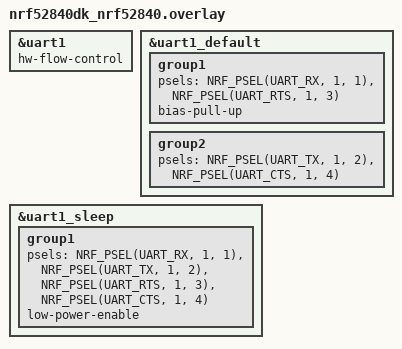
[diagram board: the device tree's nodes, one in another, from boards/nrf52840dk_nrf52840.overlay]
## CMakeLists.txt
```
#
# Copyright (c) 2024 Nordic Semiconductor ASA
#
# SPDX-License-Identifier: LicenseRef-Nordic-5-Clause
#
cmake_minimum_required(VERSION 3.20.0)

find_package(Zephyr REQUIRED HINTS $ENV{ZEPHYR_BASE})

project(nrf_rpc_remote)

# NORDIC SDK APP START
target_sources(app PRIVATE src/main.c)
# NORDIC SDK APP END

# Link OpenThread CLI even though OPENTHREAD_SHELL is not selected
zephyr_link_libraries(openthread-cli-ftd)
```

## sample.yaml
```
sample:
  name: nRF RPC application
  description: Test nRF RPC application
tests:
  sample.remote.rpc_ble:
    build_only: true
    platform_allow: >
      nrf52840dk_nrf52840
    tags: ci_build
    extra_args: >
      SNIPPET="ble"
    integration_platforms:
      - nrf52840dk_nrf52840
  sample.remote.rpc_ot:
    build_only: true
    platform_allow: >
      nrf52840dk_nrf52840
    tags: ci_build
    extra_args: >
      SNIPPET="openthread"
    integration_platforms:
      - nrf52840dk_nrf52840
  sample.remote.rpc:
    build_only: true
    platform_allow: >
      nrf52840dk_nrf52840
    tags: ci_build
    extra_args: >
      SNIPPET="ble;openthread"
    integration_platforms:
      - nrf52840dk_nrf52840
```

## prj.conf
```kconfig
#
# Copyright (c) 2024 Nordic Semiconductor
#
# SPDX-License-Identifier: LicenseRef-Nordic-5-Clause
#
CONFIG_HEAP_MEM_POOL_SIZE=4096

CONFIG_THREAD_CUSTOM_DATA=y

CONFIG_NRF_RPC=y
CONFIG_NRF_RPC_CBOR=y
CONFIG_NRF_RPC_THREAD_STACK_SIZE=4096
CONFIG_NRF_RPC_UART_TRANSPORT=y

CONFIG_UART_LINE_CTRL=y
CONFIG_UART_INTERRUPT_DRIVEN=y

CONFIG_NETWORKING=y
CONFIG_NET_L2_OPENTHREAD=y
CONFIG_OPENTHREAD_RPC=y
CONFIG_OPENTHREAD_RPC_SERVER=y
```

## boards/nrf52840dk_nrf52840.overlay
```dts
/* Copyright (c) 2024 Nordic Semiconductor ASA
 *
 * SPDX-License-Identifier: LicenseRef-Nordic-5-Clause
 */

&uart1 {
	status = "okay";
	hw-flow-control;
};

&uart1_default {
	group1 {
		psels = <NRF_PSEL(UART_RX, 1, 1)>,
			<NRF_PSEL(UART_RTS, 1, 3)>;
		bias-pull-up;
	};
	group2 {
		psels = <NRF_PSEL(UART_TX, 1, 2)>,
			<NRF_PSEL(UART_CTS, 1, 4)>;
	};
};

&uart1_sleep {
	group1 {
		psels = <NRF_PSEL(UART_RX, 1, 1)>,
			<NRF_PSEL(UART_TX, 1, 2)>,
			<NRF_PSEL(UART_RTS, 1, 3)>,
			<NRF_PSEL(UART_CTS, 1, 4)>;
		low-power-enable;
	};
};
```

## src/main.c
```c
/*
 * Copyright (c) 2024 Nordic Semiconductor ASA
 *
 * SPDX-License-Identifier: LicenseRef-Nordic-5-Clause
 */

#include <zephyr/device.h>
#include <zephyr/logging/log.h>
#include <zephyr/drivers/uart.h>

#include <zephyr/kernel.h>
#include <zephyr/device.h>

#include <nrf_rpc_tr.h>
#include <nrf_rpc/nrf_rpc_uart.h>
#include <nrf_rpc_errno.h>
#include <nrf_rpc_cbor.h>
#include <sys/errno.h>

LOG_MODULE_REGISTER(nrf_rpc_remote, CONFIG_NRF_RPC_REMOTE_LOG_LEVEL);

static void err_handler(const struct nrf_rpc_err_report *report)
{
	printk("nRF RPC error %d ocurred. See nRF RPC logs for more details.",
	       report->code);
	//k_oops();
}

static int serialization_init(void)
{

	int err;

	printk("Init begin\n");

	err = nrf_rpc_init(err_handler);
	if (err) {
		LOG_ERR("Init failed %d\n", err);
		return -NRF_EINVAL;
	}

	printk("Init done\n");

	return 0;
}

extern volatile int num_interrupts;

int main(void)
{
	int ret;

	k_sleep(K_MSEC(3000));
	ret = serialization_init();

	if (ret != 0) {
		LOG_ERR("Init RPC Failed.");
	}

	printk("Welcome to RPC remote\r\n");

	return 0;
}
```
